# RS1xxxx register map
Vendor: Silicon Lab Inc.; Series: ARMCM4; File version: 1.2
CPU: CM4 r1p0, little endian, MPU, FPU, 6 interrupt priority bits
Registers are 32-bit, read-write, reset 0x0 unless marked. A register's access mark holds for its fields unless they carry their own. Offsets are from the block's base; [hi:lo] are bit positions.

## SSI_Slave — Synchronous Serial Interface(SSI)
Base 0x45010000
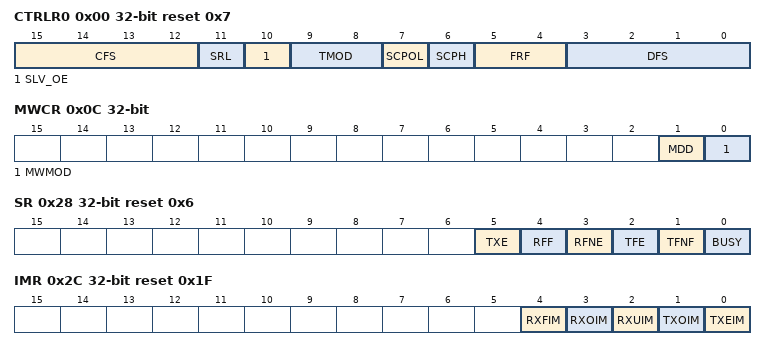
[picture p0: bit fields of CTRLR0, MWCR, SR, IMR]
0x00 CTRLR0 reset 0x7 — Control Register 0
  [15:12] CFS — Control Frame Size Selects the length of the control word for the Micro wire frame format
    0=1_Bit_Word_Control (Range -> 1 bit); 15=16_Bit_Word_Control (Range -> 16 bit)
  [11] SRL — Shift Register Loop Used for testing purposes only
    0=Normal_Mode_Operation; 1=Test_Mode_Operation
  [10] SLV_OE — DW_apb_ssi is configured as a serial-slave device
    0=None (Slave txd is enabled); 1=none (Slave txd is disabled)
  [9:8] TMOD — Selects the mode of transfer for serial communication
    0=Transmit_and_Receive; 1=Transmit Only; 2=Receive Only
  [7] SCPOL — Serial Clock Polarity. Valid when the frame format (FRF) is set to Motorola SPI
    0=Inactive_State_Low (Inactive state of serial clock is low); 1=Inactive_State_High (Inactive state of serial clock is high)
  [6] SCPH — Serial Clock Phase. Valid when the frame format (FRF) is set to Motorola SPI
    0=disable (Serial clock toggles in middle of first data bit); 1=enable (Serial clock toggles at start of first data bit)
  [5:4] FRF — Frame Format, Selects which serial protocol transfers the data
    0=Motorola_SPI; 1=Texas_Instruments_SSP; 2=National_Semi_Conductors_Micro_Wire; 3=Reserved (none)
  [3:0] DFS range 0..16 — Select the data frame length (4-bit to 16-bit serial data transfers)
0x08 SSIENR — SSI Enable Register
  [0] SSI_EN — Enables and disables all ssi operations
0x0C MWCR — Micro wire Control Register
  [1] MDD — The direction of the data word when the Micro wire serial protocol is used
    0=disable (the data word is received by the SSI MacroCell from the external serial device); 1=enable (the data word is transmitted from the SSI MacroCell to the external serial device)
  [0] MWMOD — The Micro wire transfer is sequential or non-sequential
    0=Non_Sequential_Transfer; 1=Sequential_Transfer
0x18 TXFTLR — Transmit FIFO Threshold Level Register
  [3:0] TFT — Controls the level of entries (or below) at which the transmit FIFO controller triggers an interrupt
0x1C RXFTLR — Receive FIFO Threshold Level
  [3:0] RFT — Controls the level of entries (or above) at which the receive FIFO controller triggers an interrupt
0x20 TXFLR ro — Transmit FIFO Level Register
  [4:0] TXTFL — Contains the number of valid data entries in the transmit FIFO
0x24 RXFLR ro — Receive FIFO Level Register
  [4:0] RXTFL — Contains the number of valid data entries in the receive FIFO
0x28 SR ro reset 0x6 — Status Register
  [5] TXE — Transmission Error
    on read: 0=No_Error; 1=Transmission_Error
  [4] RFF — When the receive FIFO is completely full this bit is set
    on read: 0=Receive_FIFO_Not_Full (Receive FIFO is not full); 1=Receive_FIFO_Full (Receive FIFO is full)
  [3] RFNE — Set when the receive FIFO contains one or more entries and is cleared when the receive FIFO is empty
    on read: 0=Receive_FIFO_Empty (Receive FIFO is empty); 1=Receive_FIFO_Not_Empty (Receive FIFO is not empty)
  [2] TFE — When the transmit FIFO is completely empty this bit is set
    on read: 0=Transmit_FIFO_Not_Empty (Transmit FIFO is not empty); 1=Transmit_FIFO_Empty (Transmit FIFO is empty)
  [1] TFNF — Set when the transmit FIFO contains one or more empty locations and is cleared when the FIFO is full
    on read: 0=Transmit_FIFO_Full (Transmit FIFO is full); 1=Transmit_FIFO_Not_Full (Transmit FIFO is not full)
  [0] BUSY — indicates that a serial transfer is in progress
    on read: 0=Idle (SSI is idle or disabled); 1=Transferring_Data (SSI is actively transferring data)
0x2C IMR reset 0x1F — Interrupt Mask Register
  [4] RXFIM — Receive FIFO Full Interrupt Mask
    0=Masked (ssi_rxf_intr interrupt is masked); 1=Not_Masked (ssi_rxf_intr interrupt is not masked)
  [3] RXOIM — Receive FIFO Overflow Interrupt Mask
    0=Masked (ssi_rxo_intr interrupt is masked); 1=Not_Masked (ssi_rxo_intr interrupt is not masked)
  [2] RXUIM — Receive FIFO Underflow Interrupt Mask
    0=Masked (ssi_rxu_intr interrupt is masked); 1=Not_Masked (ssi_rxu_intr interrupt is not masked)
  [1] TXOIM — Transmit FIFO Overflow Interrupt Mask
    0=Masked (ssi_txo_intr interrupt is masked); 1=Non_Masked (ssi_txo_intr interrupt is not masked)
  [0] TXEIM — Transmit FIFO Empty Interrupt Mask
    0=Masked (ssi_txe_intr interrupt is masked); 1=Not_Masked (ssi_txe_intr interrupt is not masked)
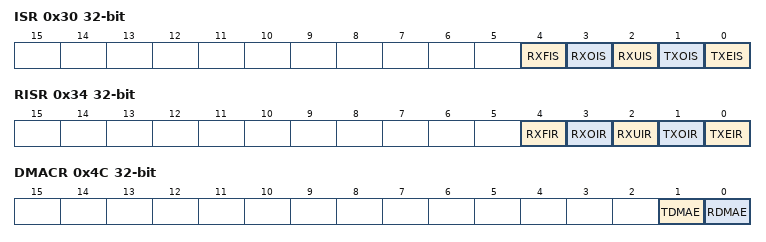
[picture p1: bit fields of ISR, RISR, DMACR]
0x30 ISR ro — Interrupt Status Register
  [4] RXFIS — Receive FIFO Full Interrupt Status
    on read: 0=Not_Active (ssi_rxf_intr interrupt is not active after masking); 1=Full (ssi_rxf_intr interrupt is full after masking)
  [3] RXOIS — Receive FIFO Overflow Interrupt Status
    on read: 0=Not_Active (ssi_rxo_intr interrupt is not active after masking); 1=Active (ssi_rxo_intr interrupt is active after masking)
  [2] RXUIS — Receive FIFO Underflow Interrupt Status
    on read: 0=Not_Active (ssi_rxu_intr interrupt is not active after masking); 1=Active (ssi_rxu_intr interrupt is active after masking)
  [1] TXOIS — Transmit FIFO Overflow Interrupt Status
    on read: 0=Not_Active (ssi_txo_intr interrupt is not active after masking); 1=Active (ssi_txo_intr interrupt is active after masking)
  [0] TXEIS — Transmit FIFO Empty Interrupt Status
    on read: 0=Not_Active (ssi_txe_intr interrupt is not active after masking); 1=Active (ssi_txe_intr interrupt is active after masking)
0x34 RISR ro — Raw Interrupt Status Register
  [4] RXFIR — Receive FIFO Full Raw Interrupt Status
    on read: 0=Not_Active (ssi_rxf_intr interrupt is not active prior to masking); 1=Active (ssi_rxf_intr interrupt is active prior to masking)
  [3] RXOIR — Receive FIFO Overflow Raw Interrupt Status
    on read: 0=Not_Active (ssi_rxo_intr interrupt is not active prior to masking); 1=Active (ssi_rxo_intr interrupt is active prior masking)
  [2] RXUIR — Receive FIFO Underflow Raw Interrupt Status
    on read: 0=Not_Active (ssi_rxu_intr interrupt is not active prior to masking); 1=Active (ssi_rxu_intr interrupt is active prior to masking)
  [1] TXOIR — Transmit FIFO Overflow Raw Interrupt Status
    on read: 0=Not_Active (ssi_txo_intr interrupt is not active prior to masking); 1=Active (1 => ssi_txo_intr interrupt is active prior masking)
  [0] TXEIR — Transmit FIFO Empty Raw Interrupt Status
    on read: 0=Not_Active (ssi_txe_intr interrupt is not active prior to masking); 1=Active (ssi_txe_intr interrupt is active prior masking)
0x38 TXOICR ro — Transmit FIFO Overflow Interrupt Clear Register
  [0] TXOICR — Clear Transmit FIFO Overflow Interrupt This register reflects the status of the interrupt
0x3C RXOICR ro — Receive FIFO Overflow Interrupt Clear Register
  [0] RXOICR — This register reflects the status of the interrupt A read from this register clears the ssi_rxo_intr interrupt
0x40 RXUICR ro — Receive FIFO Underflow Interrupt Clear Register
  [0] RXUICR — This register reflects the status of the interrupt A read from this register clears the ssi_rxu_intr interrupt
0x44 MSTICR ro — Multi-Master Interrupt Clear Register
  [0] MSTICR — This register reflects the status of the interrupt A read from this register clears the ssi_mst_intr interrupt
0x48 ICR ro — Interrupt Clear Register
  [0] ICR — This register is set if any of the interrupts below are active A read clears the ssi_txo_intr, ssi_rxu_intr, ssi_rxo_intr, and the ssi_mst_intr interrupts
0x4C DMACR — DMA Control Register
  [1] TDMAE — This bit enables/disables the transmit FIFO DMA channel
    0=disabled (Transmit DMA disabled); 1=enabled (Transmit DMA enabled)
  [0] RDMAE — This bit enables/disables the receive FIFO DMA channel
    0=disabled (Receive DMA disabled); 1=enabled (Receive DMA enabled)
0x50 DMATDLR — DMA Transmit Data Level
  [3:0] DMATDL — This bit field controls the level at which a DMA request is made by the transmit logic
0x54 DMARDLR — DMA Receive Data Level Register
  [3:0] DMARDL — This bit field controls the level at which a DMA request is made by the receive logic
0x58 IDR ro reset 0xFFFFFFFF — Identification Register
  [31:0] IDCODE — This register contains the peripherals identification code
0x5C SSI_COMP_VERSION ro reset 0x3430302A — coreKit version ID register
  [31:0] SSI_COMP_VERSION — Contains the hex representation of the Synopsys component version
0x60 DR (reset mask 0xFFFF) — Data Register
  [31:0] DR — When writing to this register must right-justify the data
